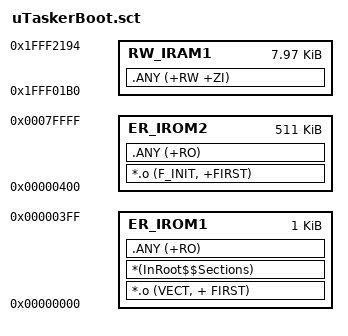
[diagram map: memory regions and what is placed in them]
; *************************************************************
; *** Scatter-Loading Description File generated by uVision ***
; *************************************************************

LR_IROM1 0x00000000 0x00000400  {    ; load region size_region
  ER_IROM1 0x00000000 0x00000400  {  ; load address = execution address
   *.o (VECT, + FIRST)
   *(InRoot$$Sections)
   .ANY (+RO)
  }
  RW_IRAM1 0x1FFF01b0 0x0001fe5  {  ; RW data
   .ANY (+RW +ZI)
  }
}

LR_IROM2 0x00000400 0x0007FC00  {
  ER_IROM2 0x00000400 0x0007FC00  {  ; load address = execution address
   *.o (F_INIT, +FIRST)
   .ANY (+RO)
  }
}
